# MCU_CTRL_MMR0_MCU_CTRL_MMR_CFG0_04500000h register map
Vendor: Texas Instruments
Peripheral module from a debugger description file (folder AM275x).
Registers are 32-bit, read-write, reset 0x0 unless marked. A register's access mark holds for its fields unless they carry their own. Offsets are as the file gives them; lines under a group give offsets from that group; [hi:lo] are bit positions; {n}, {i} and the like mark numbered series; 'fields as' and 'values as' point back to an identical list; <NAME> marks a mode.

## mcu_ctrl_mmr_CFG0 (part 1 of 2)
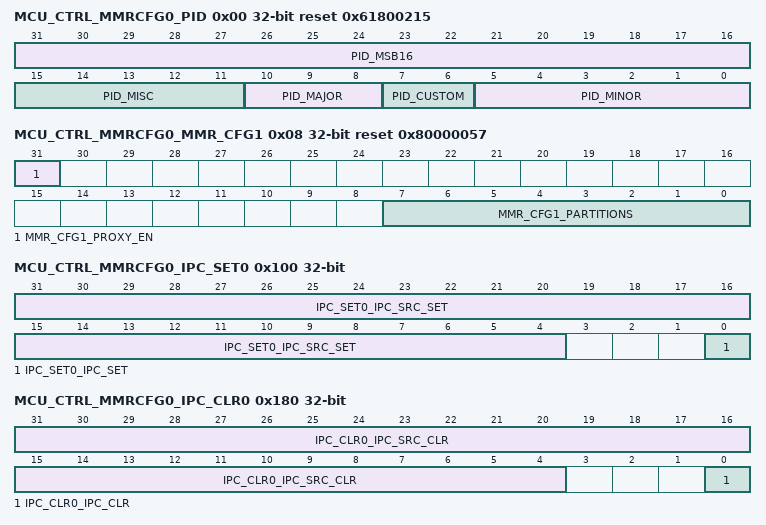
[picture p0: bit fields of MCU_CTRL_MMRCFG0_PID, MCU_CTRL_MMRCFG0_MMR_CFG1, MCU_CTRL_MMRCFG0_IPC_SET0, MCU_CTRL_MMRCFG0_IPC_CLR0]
0x00 MCU_CTRL_MMRCFG0_PID ro reset 0x61800215
  [31:16] PID_MSB16 — Reset Source: mod_g_rst_n
  [15:11] PID_MISC — Reset Source: mod_g_rst_n
  [10:8] PID_MAJOR — Reset Source: mod_g_rst_n
  [7:6] PID_CUSTOM — Reset Source: mod_g_rst_n
  [5:0] PID_MINOR — Reset Source: mod_g_rst_n
0x08 MCU_CTRL_MMRCFG0_MMR_CFG1 ro reset 0x80000057 — Indicates the MMR configuration
  [31] MMR_CFG1_PROXY_EN — Proxy addressing enabled Reset Source: mod_por_rst_n
  [7:0] MMR_CFG1_PARTITIONS — Indicates present partitions Reset Source: mod_por_rst_n
0x100 MCU_CTRL_MMRCFG0_IPC_SET0 access not given — Generate interprocessor communication interrupt to Device Manager
  [31:4] IPC_SET0_IPC_SRC_SET — Read returns 0Write: 0 - No effect 1 - Sets both corresponding IPC_CLR and the IPC_SET bits Reset Source: mod_g_rst_n (access R/W1TS)
  [0] IPC_SET0_IPC_SET — Read returns 0Write: 0 - No effect 1 - Sets both corresponding IPC_CLR and the IPC_SET bits Reset Source: mod_g_rst_n (access R/W1TS)
0x180 MCU_CTRL_MMRCFG0_IPC_CLR0 access not given — Acknowledge interprocessor communication interrupt to Device Manager
  [31:4] IPC_CLR0_IPC_SRC_CLR — Read returns current valueWrite: 0 - No effect 1 - Clears both corresponding IPC_CLR and the IPC_SET bits Reset Source: mod_g_rst_n (access R/W1TC)
  [0] IPC_CLR0_IPC_CLR — Read returns current valueWrite: 0 - No effect 1 - Clears both corresponding IPC_CLR and the IPC_SET bits Reset Source: mod_g_rst_n (access R/W1TC)
0x270 MCU_CTRL_MMRCFG0_CBA_ERR_STAT ro — Indicates addressing errors on the bus segments. Software can read this register upon receiving an mcu_cbass_err interrupt to determine the bus segment on which the error occurred.
  [24] CBA_ERR_STAT_WKUP_SAFE_CBA_ERR — Access Error from Wkup Safe CBASSField values (others are reserved):1'b0 - NO_ERROR1'b1 - ERROR Reset Source: mod_g_rst_n
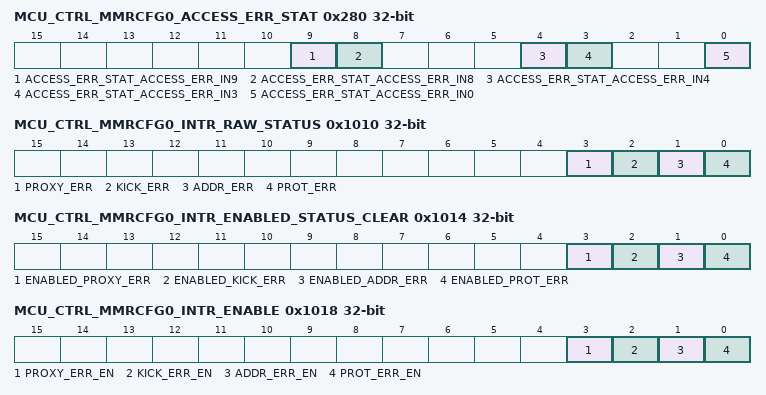
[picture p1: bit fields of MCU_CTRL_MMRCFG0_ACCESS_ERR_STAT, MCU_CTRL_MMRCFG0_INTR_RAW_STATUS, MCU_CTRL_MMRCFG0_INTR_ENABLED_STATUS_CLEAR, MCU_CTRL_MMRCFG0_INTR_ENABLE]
0x280 MCU_CTRL_MMRCFG0_ACCESS_ERR_STAT ro — Indicates an SoC MMR module access error. Software can read this register upon receiving an soc_access_err interrupt to determine the MMR module(s) where the error occurred. Interrupt status registers within the indicated MMR will provide additional details on the type of error. The access error must be cleared within the MMR for the associated access_err_in bit to be cleared.
  [9] ACCESS_ERR_STAT_ACCESS_ERR_IN9 — Access Error From MCU_PADCFG_CTRL0 MMRField values (others are reserved):1'b0 - NO_ERROR1'b1 - ERROR Reset Source: mod_por_rst_n
  [8] ACCESS_ERR_STAT_ACCESS_ERR_IN8 — Access Error From WKUP_CTRL_MMR1Field values (others are reserved):1'b0 - NO_ERROR1'b1 - ERROR Reset Source: mod_por_rst_n
  [4] ACCESS_ERR_STAT_ACCESS_ERR_IN4 — Access Error From PADCFG_CTRL0 MMRField values (others are reserved):1'b0 - NO_ERROR1'b1 - ERROR Reset Source: mod_por_rst_n
  [3] ACCESS_ERR_STAT_ACCESS_ERR_IN3 — Access Error From CTRL_MMR0Field values (others are reserved):1'b0 - NO_ERROR1'b1 - ERROR Reset Source: mod_por_rst_n
  [0] ACCESS_ERR_STAT_ACCESS_ERR_IN0 — Access Error From WKUP_CTRL_MMR0Field values (others are reserved):1'b0 - NO_ERROR1'b1 - ERROR Reset Source: mod_por_rst_n
{0x1008+0x4000*i} MCU_CTRL_MMRCFG0_LOCK{i}_KICK0 (i=0..2)
  [31:0] LOCK{i}_KICK0 — - KICK0 component Reset Source: mod_g_rst_n
{0x100C+0x4000*i} MCU_CTRL_MMRCFG0_LOCK{i}_KICK1 (i=0..2)
  [31:0] LOCK{i}_KICK1 — - KICK1 component Reset Source: mod_g_rst_n
0x1010 MCU_CTRL_MMRCFG0_INTR_RAW_STATUS access not given
  [3] PROXY_ERR — Proxy0 access violation error. Raw status is read. Write a 1 to set the status. Writing a 0 has no effect. Reset Source: mod_g_rst_n (access R/W1TS)
  [2] KICK_ERR — Kick access violation error. Raw status is read. Write a 1 to set the status. Writing a 0 has no effect. Reset Source: mod_g_rst_n (access R/W1TS)
  [1] ADDR_ERR — Addressing violation error. Raw status is read. Write a 1 to set the status. Writing a 0 has no effect. Reset Source: mod_g_rst_n (access R/W1TS)
  [0] PROT_ERR — Protection violation error. Raw status is read. Write a 1 to set the status. Writing a 0 has no effect. Reset Source: mod_g_rst_n (access R/W1TS)
0x1014 MCU_CTRL_MMRCFG0_INTR_ENABLED_STATUS_CLEAR access not given
  [3] ENABLED_PROXY_ERR — Proxy0 access violation error. Enabled status is read. Write a 1 to clear the status. Writing a 0 has no effect. Reset Source: mod_g_rst_n (access R/W1TC)
  [2] ENABLED_KICK_ERR — Kick access violation error. Enabled status is read. Write a 1 to clear the status. Writing a 0 has no effect. Reset Source: mod_g_rst_n (access R/W1TC)
  [1] ENABLED_ADDR_ERR — Addressing violation error. Enabled status is read. Write a 1 to clear the status. Writing a 0 has no effect. Reset Source: mod_g_rst_n (access R/W1TC)
  [0] ENABLED_PROT_ERR — Protection violation error. Enabled status is read. Write a 1 to clear the status. Writing a 0 has no effect. Reset Source: mod_g_rst_n (access R/W1TC)
0x1018 MCU_CTRL_MMRCFG0_INTR_ENABLE access not given
  [3] PROXY_ERR_EN — Proxy0 access violation error enable. Write a 1 to set the enable. Writing a 0 has no effect. Reset Source: mod_g_rst_n (access R/W1TS)
  [2] KICK_ERR_EN — Kick access violation error enable. Write a 1 to set the enable. Writing a 0 has no effect. Reset Source: mod_g_rst_n (access R/W1TS)
  [1] ADDR_ERR_EN — Addressing violation error enable. Write a 1 to set the enable. Writing a 0 has no effect. Reset Source: mod_g_rst_n (access R/W1TS)
  [0] PROT_ERR_EN — Protection violation error enable. Write a 1 to set the enable. Writing a 0 has no effect. Reset Source: mod_g_rst_n (access R/W1TS)
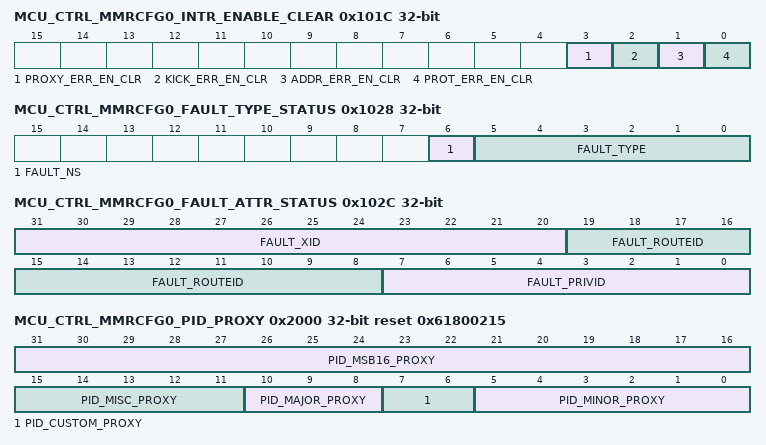
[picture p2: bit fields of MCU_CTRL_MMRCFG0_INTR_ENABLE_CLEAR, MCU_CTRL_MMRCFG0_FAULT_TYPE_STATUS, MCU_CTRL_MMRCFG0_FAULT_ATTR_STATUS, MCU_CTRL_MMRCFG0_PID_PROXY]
0x101C MCU_CTRL_MMRCFG0_INTR_ENABLE_CLEAR access not given
  [3] PROXY_ERR_EN_CLR — Proxy0 access violation error enable clear. Write a 1 to clear the enable. Writing a 0 has no effect. Reset Source: mod_g_rst_n (access R/W1TC)
  [2] KICK_ERR_EN_CLR — Kick access violation error enable clear. Write a 1 to clear the enable. Writing a 0 has no effect. Reset Source: mod_g_rst_n (access R/W1TC)
  [1] ADDR_ERR_EN_CLR — Addressing violation error enable clear. Write a 1 to clear the enable. Writing a 0 has no effect. Reset Source: mod_g_rst_n (access R/W1TC)
  [0] PROT_ERR_EN_CLR — Protection violation error enable clear. Write a 1 to clear the enable. Writing a 0 has no effect. Reset Source: mod_g_rst_n (access R/W1TC)
0x1020 MCU_CTRL_MMRCFG0_EOI
  [7:0] EOI_VECTOR — EOI vector value. Write this with interrupt distribution value in the chip. Reset Source: mod_g_rst_n
0x1024 MCU_CTRL_MMRCFG0_FAULT_ADDRESS ro
  [31:0] FAULT_ADDR — Fault Address. Reset Source: mod_g_rst_n
0x1028 MCU_CTRL_MMRCFG0_FAULT_TYPE_STATUS ro
  [6] FAULT_NS — Non-secure access. Reset Source: mod_g_rst_n
  [5:0] FAULT_TYPE — Fault Type 10_0000 = Supervisor read fault - priv = 1 dir = 1 dtype != 1 01_0000 = Supervisor write fault - priv = 1 dir = 0 00_1000 = Supervisor execute fault - priv = 1 dir = 1 dtype = 1 00_0100 = User read fault - priv = 0 dir = 1 dtype = 1 00_0010 = User write fault - priv = 0 dir = 0 00_0001 = User execute fault - priv = 0 dir = 1 dtype = 1 00_0000 = No fault Reset Source: mod_g_rst_n
0x102C MCU_CTRL_MMRCFG0_FAULT_ATTR_STATUS ro
  [31:20] FAULT_XID — XID. Reset Source: mod_g_rst_n
  [19:8] FAULT_ROUTEID — Route ID. Reset Source: mod_g_rst_n
  [7:0] FAULT_PRIVID — Privilege ID. Reset Source: mod_g_rst_n
0x1030 MCU_CTRL_MMRCFG0_FAULT_CLEAR wo
  [0] FAULT_CLR — Fault clear. Writing a 1 clears the current fault. Writing a 0 has no effect. Reset Source: mod_g_rst_n
0x1100 MCU_CTRL_MMRCFG0_CLAIMREG_P0_R0_READONLY ro
  [31:0] CLAIMREG_P0_R0_READONLY — Claim bits for Partition 0 Reset Source: mod_g_rst_n
{0x1100+4i} MCU_CTRL_MMRCFG0_CLAIMREG_P0_R{i}_READONLY ro (i=2..5)
  [31:0] CLAIMREG_P0_R{i}_READONLY — Claim bits for Partition 0 Reset Source: mod_g_rst_n
0x2000 MCU_CTRL_MMRCFG0_PID_PROXY ro reset 0x61800215
  [31:16] PID_MSB16_PROXY — Reset Source: mod_g_rst_n
  [15:11] PID_MISC_PROXY — Reset Source: mod_g_rst_n
  [10:8] PID_MAJOR_PROXY — Reset Source: mod_g_rst_n
  [7:6] PID_CUSTOM_PROXY — Reset Source: mod_g_rst_n
  [5:0] PID_MINOR_PROXY — Reset Source: mod_g_rst_n
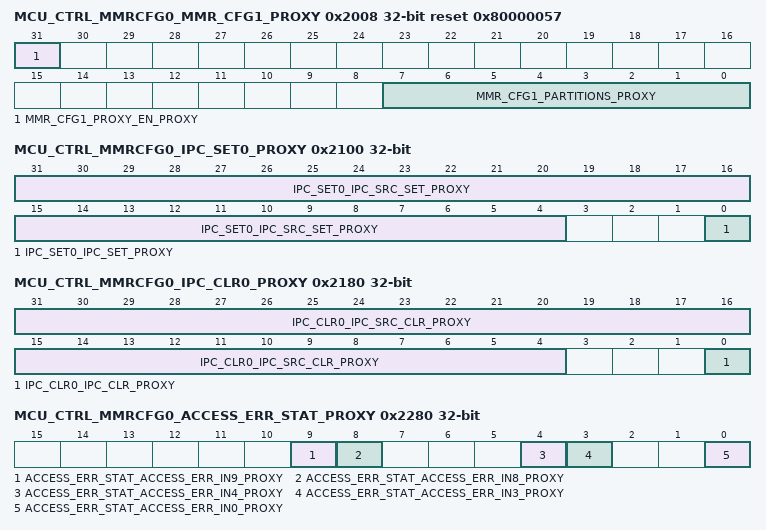
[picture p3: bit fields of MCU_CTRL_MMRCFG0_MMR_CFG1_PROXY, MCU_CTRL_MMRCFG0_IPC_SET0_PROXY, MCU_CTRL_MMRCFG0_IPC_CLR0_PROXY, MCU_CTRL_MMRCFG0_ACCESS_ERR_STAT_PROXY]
0x2008 MCU_CTRL_MMRCFG0_MMR_CFG1_PROXY ro reset 0x80000057 — Indicates the MMR configuration
  [31] MMR_CFG1_PROXY_EN_PROXY — Proxy addressing enabled Reset Source: mod_por_rst_n
  [7:0] MMR_CFG1_PARTITIONS_PROXY — Indicates present partitions Reset Source: mod_por_rst_n
0x2100 MCU_CTRL_MMRCFG0_IPC_SET0_PROXY access not given — Generate interprocessor communication interrupt to Device Manager
  [31:4] IPC_SET0_IPC_SRC_SET_PROXY — Read returns 0Write: 0 - No effect 1 - Sets both corresponding IPC_CLR and the IPC_SET bits Reset Source: mod_g_rst_n (access R/W1TS)
  [0] IPC_SET0_IPC_SET_PROXY — Read returns 0Write: 0 - No effect 1 - Sets both corresponding IPC_CLR and the IPC_SET bits Reset Source: mod_g_rst_n (access R/W1TS)
0x2180 MCU_CTRL_MMRCFG0_IPC_CLR0_PROXY access not given — Acknowledge interprocessor communication interrupt to Device Manager
  [31:4] IPC_CLR0_IPC_SRC_CLR_PROXY — Read returns current valueWrite: 0 - No effect 1 - Clears both corresponding IPC_CLR and the IPC_SET bits Reset Source: mod_g_rst_n (access R/W1TC)
  [0] IPC_CLR0_IPC_CLR_PROXY — Read returns current valueWrite: 0 - No effect 1 - Clears both corresponding IPC_CLR and the IPC_SET bits Reset Source: mod_g_rst_n (access R/W1TC)
0x2270 MCU_CTRL_MMRCFG0_CBA_ERR_STAT_PROXY ro — Indicates addressing errors on the bus segments. Software can read this register upon receiving an mcu_cbass_err interrupt to determine the bus segment on which the error occurred.
  [24] CBA_ERR_STAT_WKUP_SAFE_CBA_ERR_PROXY — Access Error from Wkup Safe CBASSField values (others are reserved):1'b0 - NO_ERROR1'b1 - ERROR Reset Source: mod_g_rst_n
0x2280 MCU_CTRL_MMRCFG0_ACCESS_ERR_STAT_PROXY ro — Indicates an SoC MMR module access error. Software can read this register upon receiving an soc_access_err interrupt to determine the MMR module(s) where the error occurred. Interrupt status registers within the indicated MMR will provide additional details on the type of error. The access error must be cleared within the MMR for the associated access_err_in bit to be cleared.
  [9] ACCESS_ERR_STAT_ACCESS_ERR_IN9_PROXY — Access Error From MCU_PADCFG_CTRL0 MMRField values (others are reserved):1'b0 - NO_ERROR1'b1 - ERROR Reset Source: mod_por_rst_n
  [8] ACCESS_ERR_STAT_ACCESS_ERR_IN8_PROXY — Access Error From WKUP_CTRL_MMR1Field values (others are reserved):1'b0 - NO_ERROR1'b1 - ERROR Reset Source: mod_por_rst_n
  [4] ACCESS_ERR_STAT_ACCESS_ERR_IN4_PROXY — Access Error From PADCFG_CTRL0 MMRField values (others are reserved):1'b0 - NO_ERROR1'b1 - ERROR Reset Source: mod_por_rst_n
  [3] ACCESS_ERR_STAT_ACCESS_ERR_IN3_PROXY — Access Error From CTRL_MMR0Field values (others are reserved):1'b0 - NO_ERROR1'b1 - ERROR Reset Source: mod_por_rst_n
  [0] ACCESS_ERR_STAT_ACCESS_ERR_IN0_PROXY — Access Error From WKUP_CTRL_MMR0Field values (others are reserved):1'b0 - NO_ERROR1'b1 - ERROR Reset Source: mod_por_rst_n
{0x3008+0x4000*i} MCU_CTRL_MMRCFG0_LOCK{i}_KICK0_PROXY (i=0..2)
  [31:0] LOCK{i}_KICK0_PROXY — - KICK0 component Reset Source: mod_g_rst_n
{0x300C+0x4000*i} MCU_CTRL_MMRCFG0_LOCK{i}_KICK1_PROXY (i=0..2)
  [31:0] LOCK{i}_KICK1_PROXY — - KICK1 component Reset Source: mod_g_rst_n
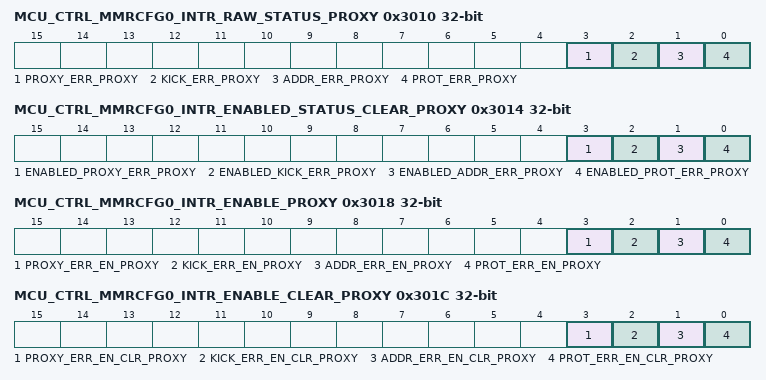
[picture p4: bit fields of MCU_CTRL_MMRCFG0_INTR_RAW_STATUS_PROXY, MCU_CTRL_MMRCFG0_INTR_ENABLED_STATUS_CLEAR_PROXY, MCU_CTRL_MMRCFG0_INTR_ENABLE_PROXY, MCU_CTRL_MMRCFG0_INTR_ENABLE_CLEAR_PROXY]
0x3010 MCU_CTRL_MMRCFG0_INTR_RAW_STATUS_PROXY access not given
  [3] PROXY_ERR_PROXY — Proxy0 access violation error. Raw status is read. Write a 1 to set the status. Writing a 0 has no effect. Reset Source: mod_g_rst_n (access R/W1TS)
  [2] KICK_ERR_PROXY — Kick access violation error. Raw status is read. Write a 1 to set the status. Writing a 0 has no effect. Reset Source: mod_g_rst_n (access R/W1TS)
  [1] ADDR_ERR_PROXY — Addressing violation error. Raw status is read. Write a 1 to set the status. Writing a 0 has no effect. Reset Source: mod_g_rst_n (access R/W1TS)
  [0] PROT_ERR_PROXY — Protection violation error. Raw status is read. Write a 1 to set the status. Writing a 0 has no effect. Reset Source: mod_g_rst_n (access R/W1TS)
0x3014 MCU_CTRL_MMRCFG0_INTR_ENABLED_STATUS_CLEAR_PROXY access not given
  [3] ENABLED_PROXY_ERR_PROXY — Proxy0 access violation error. Enabled status is read. Write a 1 to clear the status. Writing a 0 has no effect. Reset Source: mod_g_rst_n (access R/W1TC)
  [2] ENABLED_KICK_ERR_PROXY — Kick access violation error. Enabled status is read. Write a 1 to clear the status. Writing a 0 has no effect. Reset Source: mod_g_rst_n (access R/W1TC)
  [1] ENABLED_ADDR_ERR_PROXY — Addressing violation error. Enabled status is read. Write a 1 to clear the status. Writing a 0 has no effect. Reset Source: mod_g_rst_n (access R/W1TC)
  [0] ENABLED_PROT_ERR_PROXY — Protection violation error. Enabled status is read. Write a 1 to clear the status. Writing a 0 has no effect. Reset Source: mod_g_rst_n (access R/W1TC)
0x3018 MCU_CTRL_MMRCFG0_INTR_ENABLE_PROXY access not given
  [3] PROXY_ERR_EN_PROXY — Proxy0 access violation error enable. Write a 1 to set the enable. Writing a 0 has no effect. Reset Source: mod_g_rst_n (access R/W1TS)
  [2] KICK_ERR_EN_PROXY — Kick access violation error enable. Write a 1 to set the enable. Writing a 0 has no effect. Reset Source: mod_g_rst_n (access R/W1TS)
  [1] ADDR_ERR_EN_PROXY — Addressing violation error enable. Write a 1 to set the enable. Writing a 0 has no effect. Reset Source: mod_g_rst_n (access R/W1TS)
  [0] PROT_ERR_EN_PROXY — Protection violation error enable. Write a 1 to set the enable. Writing a 0 has no effect. Reset Source: mod_g_rst_n (access R/W1TS)
0x301C MCU_CTRL_MMRCFG0_INTR_ENABLE_CLEAR_PROXY access not given
  [3] PROXY_ERR_EN_CLR_PROXY — Proxy0 access violation error enable clear. Write a 1 to clear the enable. Writing a 0 has no effect. Reset Source: mod_g_rst_n (access R/W1TC)
  [2] KICK_ERR_EN_CLR_PROXY — Kick access violation error enable clear. Write a 1 to clear the enable. Writing a 0 has no effect. Reset Source: mod_g_rst_n (access R/W1TC)
  [1] ADDR_ERR_EN_CLR_PROXY — Addressing violation error enable clear. Write a 1 to clear the enable. Writing a 0 has no effect. Reset Source: mod_g_rst_n (access R/W1TC)
  [0] PROT_ERR_EN_CLR_PROXY — Protection violation error enable clear. Write a 1 to clear the enable. Writing a 0 has no effect. Reset Source: mod_g_rst_n (access R/W1TC)
0x3020 MCU_CTRL_MMRCFG0_EOI_PROXY
  [7:0] EOI_VECTOR_PROXY — EOI vector value. Write this with interrupt distribution value in the chip. Reset Source: mod_g_rst_n
0x3024 MCU_CTRL_MMRCFG0_FAULT_ADDRESS_PROXY ro
  [31:0] FAULT_ADDR_PROXY — Fault Address. Reset Source: mod_g_rst_n
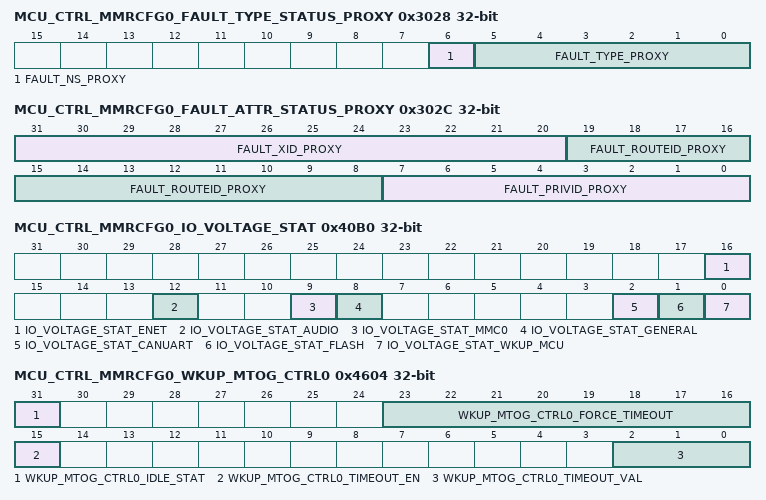
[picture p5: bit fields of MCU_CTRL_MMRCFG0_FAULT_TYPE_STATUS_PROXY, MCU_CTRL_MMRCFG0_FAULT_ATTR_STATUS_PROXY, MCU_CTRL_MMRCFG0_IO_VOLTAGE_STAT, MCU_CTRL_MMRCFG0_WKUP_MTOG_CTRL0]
0x3028 MCU_CTRL_MMRCFG0_FAULT_TYPE_STATUS_PROXY ro
  [6] FAULT_NS_PROXY — Non-secure access. Reset Source: mod_g_rst_n
  [5:0] FAULT_TYPE_PROXY — Fault Type 10_0000 = Supervisor read fault - priv = 1 dir = 1 dtype != 1 01_0000 = Supervisor write fault - priv = 1 dir = 0 00_1000 = Supervisor execute fault - priv = 1 dir = 1 dtype = 1 00_0100 = User read fault - priv = 0 dir = 1 dtype = 1 00_0010 = User write fault - priv = 0 dir = 0 00_0001 = User execute fault - priv = 0 dir = 1 dtype = 1 00_0000 = No fault Reset Source: mod_g_rst_n
0x302C MCU_CTRL_MMRCFG0_FAULT_ATTR_STATUS_PROXY ro
  [31:20] FAULT_XID_PROXY — XID. Reset Source: mod_g_rst_n
  [19:8] FAULT_ROUTEID_PROXY — Route ID. Reset Source: mod_g_rst_n
  [7:0] FAULT_PRIVID_PROXY — Privilege ID. Reset Source: mod_g_rst_n
0x3030 MCU_CTRL_MMRCFG0_FAULT_CLEAR_PROXY wo
  [0] FAULT_CLR_PROXY — Fault clear. Writing a 1 clears the current fault. Writing a 0 has no effect. Reset Source: mod_g_rst_n
{0x3100+4i} MCU_CTRL_MMRCFG0_CLAIMREG_P0_R{i} (i=0..5)
  [31:0] CLAIMREG_P0_R{i} — Claim bits for Partition 0 Reset Source: mod_g_rst_n
0x4020 MCU_CTRL_MMRCFG0_MCU_GPIO_CTRL — Controls operation of the MCU_GPIO module
  [0] MCU_GPIO_CTRL_WAKEN — Determines whether or not MCU_GPIO clock is stopped by its LPSC. Preventing the clock stop allows the MCU_GPIO to provide a wakeup event.Field values (others are reserved):1'b0 - WAKEUP_DISABLED1'b1 - WAKEUP_ENABLED Reset Source: mod_por_rst_n
{0x4080+4i} MCU_CTRL_MMRCFG0_DBOUNCE_CFG{i} (i=1..6) — Configures IO debounce selections
  [5:0] DBOUNCE_CFG{i}_DB_CFG — Configures the debounce period used for I/Os with PADCONFIGx_DEBOUNCE_SEL = {i}. Debounce period is specified as a number of CLK0 or CLK1 clock cycles. For all inputs CLK0 is CLK_32K_RC and CLK1 is HFOSC0_CLKOUT.Field values (others are reserved):6'b000000 - BYPASS6'b000001 - DB_64_CLK06'b000010 - DB_96_CLK06'b000011 - DB_128_CLK06'b000100 - DB_160_CLK06'b000101 - DB_192_CLK06'b000110 - DB_224_CLK06'b000111 - DB_256_CLK06'b001000 - DB_288_CLK06'b001001 - DB_320_CLK06'b001010 - DB_352_CLK06'b001011 - DB_384_CLK06'b001100 - DB_416_CLK06'b001101 - DB_448_CLK06'b001110 - DB_480_CLK06'b001111 - DB_512_CLK06'b010000 - DB_544_CLK06'b010001 - DB_576_CLK06'b010010 - DB_608_CLK06'b010011 - DB_640_CLK06'b010100 - DB_672_CLK06'b010101 - DB_704_CLK06'b010110 - DB_512_CLK06'b010111 - DB_1024_CLK06'b011000 - DB_1536_CLK06'b011001 - DB_2048_CLK06'b011010 - DB_2560_CLK06'b011011 - DB_3072_CLK06'b011100 - DB_3584_CLK06'b011101 - DB_4096_CLK06'b011110 - DB_4608_CLK06'b011111 - DB_5120_CLK06'b100000 - DB_1_CLK16'b100001 - DB_2_CLK16'b100010 - DB_3_CLK16'b100011 - DB_4_CLK16'b100100 - DB_5_CLK16'b100101 - DB_6_CLK16'b100110 - DB_7_CLK16'b100111 - DB_8_CLK16'b101000 - DB_9_CLK16'b101001 - DB_10_CLK16'b101010 - DB_11_CLK16'b101011 - DB_12_CLK16'b101100 - DB_13_CLK16'b101101 - DB_14_CLK16'b101110 - DB_15_CLK16'b101111 - DB_16_CLK16'b110000 - DB_17_CLK16'b110001 - DB_18_CLK16'b110010 - DB_19_CLK16'b110011 - DB_20_CLK16'b110100 - DB_21_CLK16'b110101 - DB_22_CLK16'b110110 - DB_512_CLK16'b110111 - DB_1024_CLK16'b111000 - DB_1536_CLK16'b111001 - DB_2048_CLK16'b111010 - DB_2560_CLK16'b111011 - DB_3072_CLK16'b111100 - DB_3584_CLK16'b111101 - DB_4096_CLK16'b111110 - DB_4608_CLK16'b111111 - DB_5120_CLK1 Reset Source: mod_por_rst_n
0x40B0 MCU_CTRL_MMRCFG0_IO_VOLTAGE_STAT ro — Reads returns the current value detected by the IO voltage mode circuit for each dual rail I/O Group.
  [16] IO_VOLTAGE_STAT_ENET — Detected voltage for the ENET I/O group (VDDSHV2)Field values (others are reserved):1'b0 - IOGROUP_3P3V1'b1 - IOGROUP_1P8V Reset Source: mod_por_rst_n
  [12] IO_VOLTAGE_STAT_AUDIO — Detected voltage for the AUDIO I/O group (VDDSHV3)Field values (others are reserved):1'b0 - IOGROUP_3P3V1'b1 - IOGROUP_1P8V Reset Source: mod_por_rst_n
  [9] IO_VOLTAGE_STAT_MMC0 — Detected voltage for the MMC0 I/O group (VDDSHV4)Field values (others are reserved):1'b0 - IOGROUP_3P3V1'b1 - IOGROUP_1P8V Reset Source: mod_por_rst_n
  [8] IO_VOLTAGE_STAT_GENERAL — Detected voltage for the General I/O group (VDDSHV0)Field values (others are reserved):1'b0 - IOGROUP_3P3V1'b1 - IOGROUP_1P8V Reset Source: mod_por_rst_n
  [2] IO_VOLTAGE_STAT_CANUART — Detected voltage for the CANUART I/O group (VDDSHV_WKUP)Field values (others are reserved):1'b0 - IOGROUP_3P3V1'b1 - IOGROUP_1P8V Reset Source: mod_por_rst_n
  [1] IO_VOLTAGE_STAT_FLASH — Detected voltage for the Flash I/O group (VDDSHV1)Field values (others are reserved):1'b0 - IOGROUP_3P3V1'b1 - IOGROUP_1P8V Reset Source: mod_por_rst_n
  [0] IO_VOLTAGE_STAT_WKUP_MCU — Detected voltage for the WKUP_MCU I/O group (VDDSHV_MCU)Field values (others are reserved):1'b0 - IOGROUP_3P3V1'b1 - IOGROUP_1P8V Reset Source: mod_por_rst_n
0x4604 MCU_CTRL_MMRCFG0_WKUP_MTOG_CTRL0 access per field — Controls the dm2ws WKUP_TIMEOUT0 gasket
  [31] WKUP_MTOG_CTRL0_IDLE_STAT ro — Idle statusWhen high, indicates MTOGundefined is idle.Field values (others are reserved):1'b0 - BUSY1'b1 - IDLE Reset Source: mod_g_rst_n
  [23:16] WKUP_MTOG_CTRL0_FORCE_TIMEOUT rw — Force TimoutThis is a fault tolerant bitfield.Forces a flush of the interface transactions. This bitfield is only relevant if timeout_en=1. After forcing a timeout by Writing the encoded value, the force_timeout and timeout_en bitfields mut be cleared to clear the timeout before re-enabling the gasket.Field values (others are reserved):8'h00 - CLEAR_TIMEOUT8'h95 - FORCE_TIMEOUT Reset Source: mod_g_rst_n
  [15] WKUP_MTOG_CTRL0_TIMEOUT_EN rw — Timeout Gasket EnableField values (others are reserved):1'b0 - DISABLED (write 0 to clear the interrupt and reset the gasket counter)1'b1 - ENABLED Reset Source: mod_g_rst_n
  [2:0] WKUP_MTOG_CTRL0_TIMEOUT_VAL rw — Gasket Timeout ValueSelects the number of clock cycles before the interface is considered to have timed outField values (others are reserved):3'b000 - TO_1K_CYCLES3'b001 - TO_4K_CYCLES3'b010 - TO_16K_CYCLES3'b011 - TO_64K_CYCLES3'b100 - TO_256K_CYCLES3'b101 - TO_1024K_CYCLES3'b110 - TO_2048K_CYCLES3'b111 - TO_4096K_CYCLES Reset Source: mod_g_rst_n
0x4610 MCU_CTRL_MMRCFG0_TOG_STAT ro — Contains the status of each Timeout Gasket, to be read in ISR to determine which timeout gasket caused an interrupt.
  [1:0] TOG_STAT_MST_TOG_STAT — Error Status of Initiator Timeout GasketsField values (others are reserved):undefined - undefinedundefined - undefined2'b01 - RESERVED2'b10 - WKUP_TIMEOUT0undefined - undefined2'b11 - RESERVED Reset Source: mod_g_rst_n
{0x5100+4i} MCU_CTRL_MMRCFG0_CLAIMREG_P1_R{i}_READONLY ro (i=0..2)
  [31:0] CLAIMREG_P1_R{i}_READONLY — Claim bits for Partition 1 Reset Source: mod_g_rst_n
0x6020 MCU_CTRL_MMRCFG0_MCU_GPIO_CTRL_PROXY — Controls operation of the MCU_GPIO module
  [0] MCU_GPIO_CTRL_WAKEN_PROXY — Determines whether or not MCU_GPIO clock is stopped by its LPSC. Preventing the clock stop allows the MCU_GPIO to provide a wakeup event.Field values (others are reserved):1'b0 - WAKEUP_DISABLED1'b1 - WAKEUP_ENABLED Reset Source: mod_por_rst_n
{0x6080+4i} MCU_CTRL_MMRCFG0_DBOUNCE_CFG{i}_PROXY (i=1..6) — Configures IO debounce selections
  [5:0] DBOUNCE_CFG{i}_DB_CFG_PROXY — Configures the debounce period used for I/Os with PADCONFIGx_DEBOUNCE_SEL = {i}. Debounce period is specified as a number of CLK0 or CLK1 clock cycles. For all inputs CLK0 is CLK_32K_RC and CLK1 is HFOSC0_CLKOUT.Field values (others are reserved):6'b000000 - BYPASS6'b000001 - DB_64_CLK06'b000010 - DB_96_CLK06'b000011 - DB_128_CLK06'b000100 - DB_160_CLK06'b000101 - DB_192_CLK06'b000110 - DB_224_CLK06'b000111 - DB_256_CLK06'b001000 - DB_288_CLK06'b001001 - DB_320_CLK06'b001010 - DB_352_CLK06'b001011 - DB_384_CLK06'b001100 - DB_416_CLK06'b001101 - DB_448_CLK06'b001110 - DB_480_CLK06'b001111 - DB_512_CLK06'b010000 - DB_544_CLK06'b010001 - DB_576_CLK06'b010010 - DB_608_CLK06'b010011 - DB_640_CLK06'b010100 - DB_672_CLK06'b010101 - DB_704_CLK06'b010110 - DB_512_CLK06'b010111 - DB_1024_CLK06'b011000 - DB_1536_CLK06'b011001 - DB_2048_CLK06'b011010 - DB_2560_CLK06'b011011 - DB_3072_CLK06'b011100 - DB_3584_CLK06'b011101 - DB_4096_CLK06'b011110 - DB_4608_CLK06'b011111 - DB_5120_CLK06'b100000 - DB_1_CLK16'b100001 - DB_2_CLK16'b100010 - DB_3_CLK16'b100011 - DB_4_CLK16'b100100 - DB_5_CLK16'b100101 - DB_6_CLK16'b100110 - DB_7_CLK16'b100111 - DB_8_CLK16'b101000 - DB_9_CLK16'b101001 - DB_10_CLK16'b101010 - DB_11_CLK16'b101011 - DB_12_CLK16'b101100 - DB_13_CLK16'b101101 - DB_14_CLK16'b101110 - DB_15_CLK16'b101111 - DB_16_CLK16'b110000 - DB_17_CLK16'b110001 - DB_18_CLK16'b110010 - DB_19_CLK16'b110011 - DB_20_CLK16'b110100 - DB_21_CLK16'b110101 - DB_22_CLK16'b110110 - DB_512_CLK16'b110111 - DB_1024_CLK16'b111000 - DB_1536_CLK16'b111001 - DB_2048_CLK16'b111010 - DB_2560_CLK16'b111011 - DB_3072_CLK16'b111100 - DB_3584_CLK16'b111101 - DB_4096_CLK16'b111110 - DB_4608_CLK16'b111111 - DB_5120_CLK1 Reset Source: mod_por_rst_n
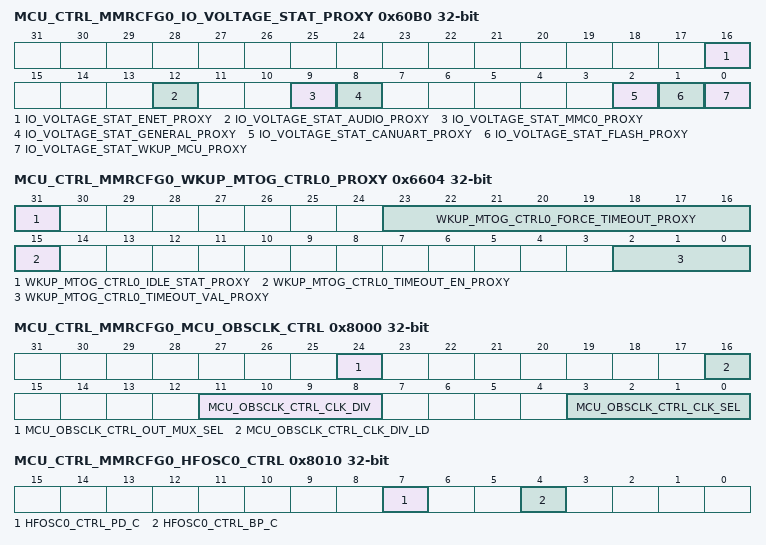
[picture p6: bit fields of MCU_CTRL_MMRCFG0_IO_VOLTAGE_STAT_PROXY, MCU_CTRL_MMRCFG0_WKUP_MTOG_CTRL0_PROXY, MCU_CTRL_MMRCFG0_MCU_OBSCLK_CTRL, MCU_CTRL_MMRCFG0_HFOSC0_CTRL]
0x60B0 MCU_CTRL_MMRCFG0_IO_VOLTAGE_STAT_PROXY ro — Reads returns the current value detected by the IO voltage mode circuit for each dual rail I/O Group.
  [16] IO_VOLTAGE_STAT_ENET_PROXY — Detected voltage for the ENET I/O group (VDDSHV2)Field values (others are reserved):1'b0 - IOGROUP_3P3V1'b1 - IOGROUP_1P8V Reset Source: mod_por_rst_n
  [12] IO_VOLTAGE_STAT_AUDIO_PROXY — Detected voltage for the AUDIO I/O group (VDDSHV3)Field values (others are reserved):1'b0 - IOGROUP_3P3V1'b1 - IOGROUP_1P8V Reset Source: mod_por_rst_n
  [9] IO_VOLTAGE_STAT_MMC0_PROXY — Detected voltage for the MMC0 I/O group (VDDSHV4)Field values (others are reserved):1'b0 - IOGROUP_3P3V1'b1 - IOGROUP_1P8V Reset Source: mod_por_rst_n
  [8] IO_VOLTAGE_STAT_GENERAL_PROXY — Detected voltage for the General I/O group (VDDSHV0)Field values (others are reserved):1'b0 - IOGROUP_3P3V1'b1 - IOGROUP_1P8V Reset Source: mod_por_rst_n
  [2] IO_VOLTAGE_STAT_CANUART_PROXY — Detected voltage for the CANUART I/O group (VDDSHV_WKUP)Field values (others are reserved):1'b0 - IOGROUP_3P3V1'b1 - IOGROUP_1P8V Reset Source: mod_por_rst_n
  [1] IO_VOLTAGE_STAT_FLASH_PROXY — Detected voltage for the Flash I/O group (VDDSHV1)Field values (others are reserved):1'b0 - IOGROUP_3P3V1'b1 - IOGROUP_1P8V Reset Source: mod_por_rst_n
  [0] IO_VOLTAGE_STAT_WKUP_MCU_PROXY — Detected voltage for the WKUP_MCU I/O group (VDDSHV_MCU)Field values (others are reserved):1'b0 - IOGROUP_3P3V1'b1 - IOGROUP_1P8V Reset Source: mod_por_rst_n
0x6604 MCU_CTRL_MMRCFG0_WKUP_MTOG_CTRL0_PROXY access per field — Controls the dm2ws WKUP_TIMEOUT0 gasket
  [31] WKUP_MTOG_CTRL0_IDLE_STAT_PROXY ro — Idle statusWhen high, indicates MTOGundefined is idle.Field values (others are reserved):1'b0 - BUSY1'b1 - IDLE Reset Source: mod_g_rst_n
  [23:16] WKUP_MTOG_CTRL0_FORCE_TIMEOUT_PROXY rw — Force TimoutThis is a fault tolerant bitfield.Forces a flush of the interface transactions. This bitfield is only relevant if timeout_en=1. After forcing a timeout by Writing the encoded value, the force_timeout and timeout_en bitfields mut be cleared to clear the timeout before re-enabling the gasket.Field values (others are reserved):8'h00 - CLEAR_TIMEOUT8'h95 - FORCE_TIMEOUT Reset Source: mod_g_rst_n
  [15] WKUP_MTOG_CTRL0_TIMEOUT_EN_PROXY rw — Timeout Gasket EnableField values (others are reserved):1'b0 - DISABLED (write 0 to clear the interrupt and reset the gasket counter)1'b1 - ENABLED Reset Source: mod_g_rst_n
  [2:0] WKUP_MTOG_CTRL0_TIMEOUT_VAL_PROXY rw — Gasket Timeout ValueSelects the number of clock cycles before the interface is considered to have timed outField values (others are reserved):3'b000 - TO_1K_CYCLES3'b001 - TO_4K_CYCLES3'b010 - TO_16K_CYCLES3'b011 - TO_64K_CYCLES3'b100 - TO_256K_CYCLES3'b101 - TO_1024K_CYCLES3'b110 - TO_2048K_CYCLES3'b111 - TO_4096K_CYCLES Reset Source: mod_g_rst_n
0x6610 MCU_CTRL_MMRCFG0_TOG_STAT_PROXY ro — Contains the status of each Timeout Gasket, to be read in ISR to determine which timeout gasket caused an interrupt.
  [1:0] TOG_STAT_MST_TOG_STAT_PROXY — Error Status of Initiator Timeout GasketsField values (others are reserved):undefined - undefinedundefined - undefined2'b01 - RESERVED2'b10 - WKUP_TIMEOUT0undefined - undefined2'b11 - RESERVED Reset Source: mod_g_rst_n
{0x7100+4i} MCU_CTRL_MMRCFG0_CLAIMREG_P1_R{i} (i=0..12)
  [31:0] CLAIMREG_P1_R{i} — Claim bits for Partition 1 Reset Source: mod_g_rst_n
0x8000 MCU_CTRL_MMRCFG0_MCU_OBSCLK_CTRL — Controls which internal clock is made observable on the MCU_OBSCLK output pin
  [24] MCU_OBSCLK_CTRL_OUT_MUX_SEL — MCU_OBSCLK pin output mux selection.Note, HFOSC0_CLK is a direct output from the HFOSC0, distinct from HFOSC0_CLKOUT.Note, when HFOSC0_CLK is selected (1'b1) the MCU_OBSCLK_CTRL_clk_sel field must be programmed to 4'b0001.Field values (others are reserved):1'b0 - CLK_DIV_OUT1'b1 - HFOSC0_CLK (clk_sel must be OFF) Reset Source: mod_por_rst_n
  [16] MCU_OBSCLK_CTRL_CLK_DIV_LD — Load the output divider valueWriting 1 to this bit will generate a load pulse to load the OBSCLK divider value. This bit can be cleared but must not be set in the same write cycle in which the clk_div value is changed. Field values (others are reserved):1'b0 - READY1'b1 - LOAD Reset Source: mod_por_rst_n
  [11:8] MCU_OBSCLK_CTRL_CLK_DIV — MCU_OBSCLK pin clock selection output dividerOutput clock is divided by clk_div+1 Reset Source: mod_por_rst_n
  [3:0] MCU_OBSCLK_CTRL_CLK_SEL — MCU_OBSCLK pin clock selectionField values (others are reserved):4'b0000 - CLK_12M_RC4'b0001 - OFF4'b0010 - MCU_PLL0_HSDIV0_CLKOUT4'b0011 - MCU_PLL0_HSDIV4_CLKOUT4'b0100 - MCU_PLLCTRL_OBSCLK4'b0101 - CLK_32K_RC4'b0110 - HFOSC0_CLKOUT4'b0111 - HFOSC0_CLKOUT_32K4'b1000 - MCU_SYSCLK04'b1001 - DEVICE_CLKOUT_32K Reset Source: mod_por_rst_n
0x8010 MCU_CTRL_MMRCFG0_HFOSC0_CTRL — Controls the operation of oscillator 0
  [7] HFOSC0_CTRL_PD_C — Oscillator powerdown control. When set, oscillator is disabled. Oscillator output is tristated if bp_c=0Field values (others are reserved):1'b0 - ACTIVE1'b1 - POWERDOWN Reset Source: mod_por_rst_n
  [4] HFOSC0_CTRL_BP_C — Must write '0' Reset Source: mod_por_rst_n
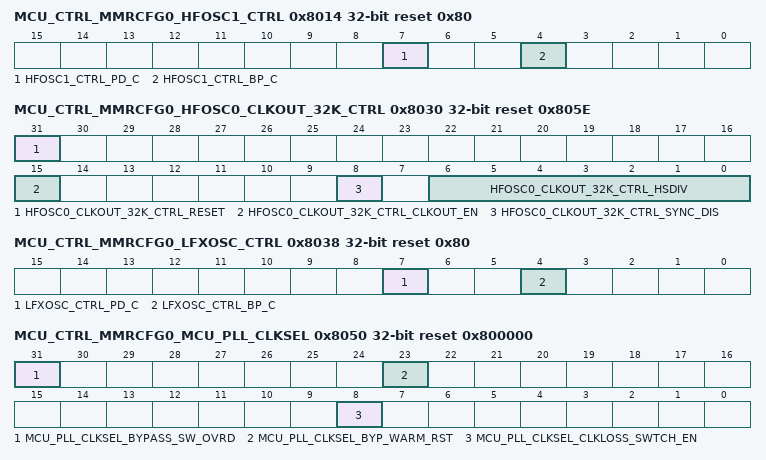
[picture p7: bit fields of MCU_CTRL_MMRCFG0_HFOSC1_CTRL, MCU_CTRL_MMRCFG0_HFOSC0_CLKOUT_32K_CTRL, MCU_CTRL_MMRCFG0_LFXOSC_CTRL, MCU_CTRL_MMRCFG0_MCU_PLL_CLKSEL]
0x8014 MCU_CTRL_MMRCFG0_HFOSC1_CTRL reset 0x80 — Controls the operation of oscillator 1
  [7] HFOSC1_CTRL_PD_C — Oscillator powerdown control. When set, oscillator is disabled. Oscillator output is tristated if bp_c=0Field values (others are reserved):1'b0 - ACTIVE1'b1 - POWERDOWN Reset Source: mod_por_rst_n
  [4] HFOSC1_CTRL_BP_C — Must write '0' Reset Source: mod_por_rst_n
0x8020 MCU_CTRL_MMRCFG0_HFOSC0_STAT access not given reset not defined — Allows status of the HFOSC Power Down by DM to be read by Top Level.
0x8030 MCU_CTRL_MMRCFG0_HFOSC0_CLKOUT_32K_CTRL reset 0x805E — Controls the HSDIV that generates a 32KHz RT clock from the HFOSC0 Crystal
  [31] HFOSC0_CLKOUT_32K_CTRL_RESET — Asynchronous Divider Reset.Field values (others are reserved):1'b0 - ACTIVE1'b1 - RESET Reset Source: sys_por_rst_n
  [15] HFOSC0_CLKOUT_32K_CTRL_CLKOUT_EN — HFOSC0_CLKOUT_32K output activeField values (others are reserved):1'b0 - Disabled1'b1 - Enabled Reset Source: sys_por_rst_n
  [8] HFOSC0_CLKOUT_32K_CTRL_SYNC_DIS — HFOSC0_CLKOUT_32K Synchronize DisableThis bit must be written 0.Field values (others are reserved):1'b0 - NORMAL Reset Source: sys_por_rst_n
  [6:0] HFOSC0_CLKOUT_32K_CTRL_HSDIV — HFOSC0_CLKOUT_32K divider:HFOSC0_CLKKOUT_32K Frequency = HFOSC0 Frequency / [8 * (hsdiv + 1)]Ex. HFOSC0 Frequency = 25MHz. hsdiv = 94 (Default)HFOSC0_CLKOUT_32K = 25MHz / (8 * (94+1)) = 26MHz / 760 = 32.894 kHz Reset Source: sys_por_rst_n
0x8038 MCU_CTRL_MMRCFG0_LFXOSC_CTRL reset 0x80 — Controls the operation of the low frequency oscillator
  [7] LFXOSC_CTRL_PD_C — Oscillator powerdown control. When set, oscillator is disabled. Oscillator output is tristated if bp_c=0Field values (others are reserved):1'b0 - ACTIVE1'b1 - POWERDOWN Reset Source: mod_por_rst_n
  [4] LFXOSC_CTRL_BP_C — Oscillator bypass control. When set, oscillator is in bypass modeField values (others are reserved):1'b0 - ACTIVE1'b1 - BYPASS Reset Source: mod_por_rst_n
0x8050 MCU_CTRL_MMRCFG0_MCU_PLL_CLKSEL reset 0x800000 — Controls the clock source for MCU PLL
  [31] MCU_PLL_CLKSEL_BYPASS_SW_OVRD — PLL Bypass warm reset software overrideWhen set, enables software control of exit from bypass mode on a mcu_reset_z for MCU_PLL0. This bit must not be set until after the corresponding byp_warm_rst bit has been cleared or the PLL will immediately enter bypass mode.Field values (others are reserved):1'b0 - Disable Software control of exit from bypass mode1'b1 - Enable Software control of exit from bypass mode Reset Source: sys_por_rst_n
  [23] MCU_PLL_CLKSEL_BYP_WARM_RST — PLL bypass mode after warm reset.This bit is only valid when bypass_sw_ovrd is set to 1'b1 to enable bypass software override.This bit is set (1'b1) when a MCU warm reset occurs and will keep MCU_PLL0 in bypass mode after reset exit until cleared by software.Field values (others are reserved):1'b0 - EXIT_BYPASS1'b1 - MAINTAIN_BYPASS Reset Source: mcu_chip1_rst_n
  [8] MCU_PLL_CLKSEL_CLKLOSS_SWTCH_EN — When set, enables automatic switching of MCU_PLL0 clock source to CLK_12M_RC if HFOSC0 clock loss is detectedField values (others are reserved):1'b0 - Disable clock source switching on clock loss1'b1 - Enable clock source switching on clock loss Reset Source: mod_por_rst_n
0x8058 MCU_CTRL_MMRCFG0_DEVICE_CLKOUT_32K_CTRL — Selects which 32KHz Clock Source provides the 32KHz clock to the Device.
  [1:0] DEVICE_CLKOUT_32K_CTRL_CLK_32K_RC_SEL — Selects the source of the device level 32KHz ClockField values (others are reserved):2'b00 - CLK_32K_RC2'b01 - HFOSC0_CLKOUT_32Kundefined - undefined2'b11 - LFOSC0_CLKOUT Reset Source: mod_g_rst_n
0x8070 MCU_CTRL_MMRCFG0_MCU_GPIO_CLKSEL access not given reset not defined — Controls the functional clock source for MCU_GPIO
0x9100 MCU_CTRL_MMRCFG0_CLAIMREG_P2_R0_READONLY ro
  [31:0] CLAIMREG_P2_R0_READONLY — Claim bits for Partition 2 Reset Source: mod_g_rst_n
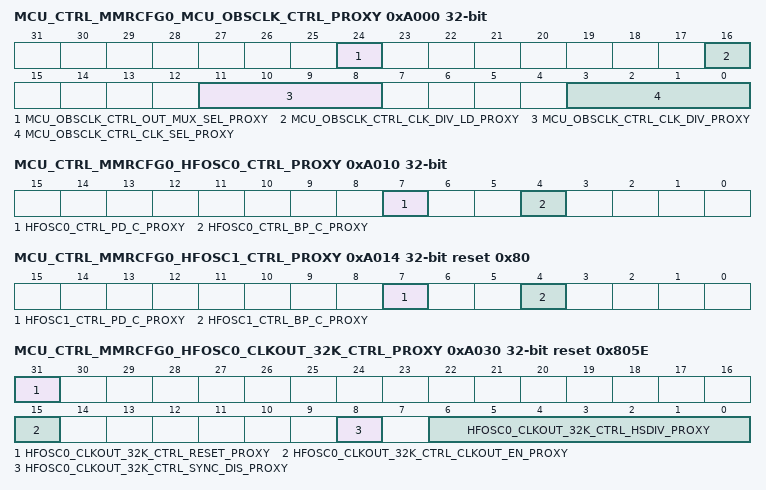
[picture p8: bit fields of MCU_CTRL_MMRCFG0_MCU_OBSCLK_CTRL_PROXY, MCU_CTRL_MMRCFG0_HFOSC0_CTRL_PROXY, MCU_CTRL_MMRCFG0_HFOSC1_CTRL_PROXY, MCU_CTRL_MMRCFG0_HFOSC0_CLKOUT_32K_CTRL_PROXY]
0xA000 MCU_CTRL_MMRCFG0_MCU_OBSCLK_CTRL_PROXY — Controls which internal clock is made observable on the MCU_OBSCLK output pin
  [24] MCU_OBSCLK_CTRL_OUT_MUX_SEL_PROXY — MCU_OBSCLK pin output mux selection.Note, HFOSC0_CLK is a direct output from the HFOSC0, distinct from HFOSC0_CLKOUT.Note, when HFOSC0_CLK is selected (1'b1) the MCU_OBSCLK_CTRL_clk_sel field must be programmed to 4'b0001.Field values (others are reserved):1'b0 - CLK_DIV_OUT1'b1 - HFOSC0_CLK (clk_sel must be OFF) Reset Source: mod_por_rst_n
  [16] MCU_OBSCLK_CTRL_CLK_DIV_LD_PROXY — Load the output divider valueWriting 1 to this bit will generate a load pulse to load the OBSCLK divider value. This bit can be cleared but must not be set in the same write cycle in which the clk_div value is changed. Field values (others are reserved):1'b0 - READY1'b1 - LOAD Reset Source: mod_por_rst_n
  [11:8] MCU_OBSCLK_CTRL_CLK_DIV_PROXY — MCU_OBSCLK pin clock selection output dividerOutput clock is divided by clk_div+1 Reset Source: mod_por_rst_n
  [3:0] MCU_OBSCLK_CTRL_CLK_SEL_PROXY — MCU_OBSCLK pin clock selectionField values (others are reserved):4'b0000 - CLK_12M_RC4'b0001 - OFF4'b0010 - MCU_PLL0_HSDIV0_CLKOUT4'b0011 - MCU_PLL0_HSDIV4_CLKOUT4'b0100 - MCU_PLLCTRL_OBSCLK4'b0101 - CLK_32K_RC4'b0110 - HFOSC0_CLKOUT4'b0111 - HFOSC0_CLKOUT_32K4'b1000 - MCU_SYSCLK04'b1001 - DEVICE_CLKOUT_32K Reset Source: mod_por_rst_n
0xA010 MCU_CTRL_MMRCFG0_HFOSC0_CTRL_PROXY — Controls the operation of oscillator 0
  [7] HFOSC0_CTRL_PD_C_PROXY — Oscillator powerdown control. When set, oscillator is disabled. Oscillator output is tristated if bp_c=0Field values (others are reserved):1'b0 - ACTIVE1'b1 - POWERDOWN Reset Source: mod_por_rst_n
  [4] HFOSC0_CTRL_BP_C_PROXY — Must write '0' Reset Source: mod_por_rst_n
0xA014 MCU_CTRL_MMRCFG0_HFOSC1_CTRL_PROXY reset 0x80 — Controls the operation of oscillator 1
  [7] HFOSC1_CTRL_PD_C_PROXY — Oscillator powerdown control. When set, oscillator is disabled. Oscillator output is tristated if bp_c=0Field values (others are reserved):1'b0 - ACTIVE1'b1 - POWERDOWN Reset Source: mod_por_rst_n
  [4] HFOSC1_CTRL_BP_C_PROXY — Must write '0' Reset Source: mod_por_rst_n
0xA020 MCU_CTRL_MMRCFG0_HFOSC0_STAT_PROXY access not given reset not defined — Allows status of the HFOSC Power Down by DM to be read by Top Level.
0xA030 MCU_CTRL_MMRCFG0_HFOSC0_CLKOUT_32K_CTRL_PROXY reset 0x805E — Controls the HSDIV that generates a 32KHz RT clock from the HFOSC0 Crystal
  [31] HFOSC0_CLKOUT_32K_CTRL_RESET_PROXY — Asynchronous Divider Reset.Field values (others are reserved):1'b0 - ACTIVE1'b1 - RESET Reset Source: sys_por_rst_n
  [15] HFOSC0_CLKOUT_32K_CTRL_CLKOUT_EN_PROXY — HFOSC0_CLKOUT_32K output activeField values (others are reserved):1'b0 - Disabled1'b1 - Enabled Reset Source: sys_por_rst_n
  [8] HFOSC0_CLKOUT_32K_CTRL_SYNC_DIS_PROXY — HFOSC0_CLKOUT_32K Synchronize DisableThis bit must be written 0.Field values (others are reserved):1'b0 - NORMAL Reset Source: sys_por_rst_n
  [6:0] HFOSC0_CLKOUT_32K_CTRL_HSDIV_PROXY — HFOSC0_CLKOUT_32K divider:HFOSC0_CLKKOUT_32K Frequency = HFOSC0 Frequency / [8 * (hsdiv + 1)]Ex. HFOSC0 Frequency = 25MHz. hsdiv = 94 (Default)HFOSC0_CLKOUT_32K = 25MHz / (8 * (94+1)) = 26MHz / 760 = 32.894 kHz Reset Source: sys_por_rst_n
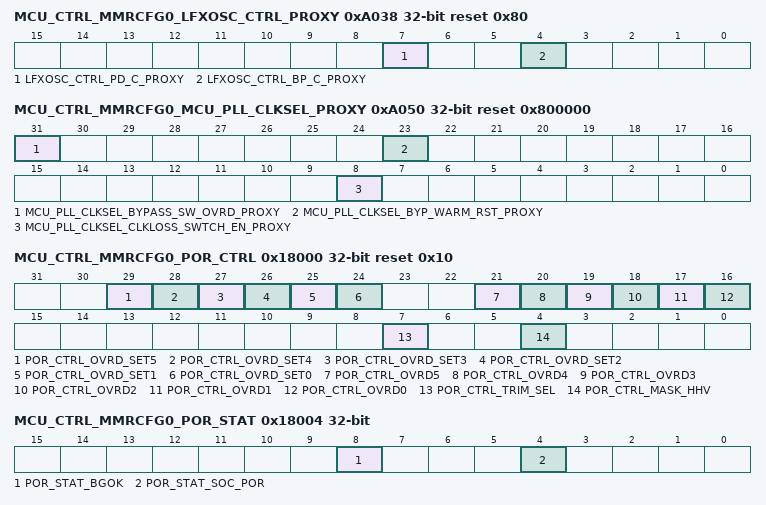
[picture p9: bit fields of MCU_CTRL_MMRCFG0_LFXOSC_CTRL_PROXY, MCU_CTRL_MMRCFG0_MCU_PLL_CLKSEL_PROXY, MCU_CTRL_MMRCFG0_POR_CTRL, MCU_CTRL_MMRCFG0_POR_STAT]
0xA038 MCU_CTRL_MMRCFG0_LFXOSC_CTRL_PROXY reset 0x80 — Controls the operation of the low frequency oscillator
  [7] LFXOSC_CTRL_PD_C_PROXY — Oscillator powerdown control. When set, oscillator is disabled. Oscillator output is tristated if bp_c=0Field values (others are reserved):1'b0 - ACTIVE1'b1 - POWERDOWN Reset Source: mod_por_rst_n
  [4] LFXOSC_CTRL_BP_C_PROXY — Oscillator bypass control. When set, oscillator is in bypass modeField values (others are reserved):1'b0 - ACTIVE1'b1 - BYPASS Reset Source: mod_por_rst_n
0xA050 MCU_CTRL_MMRCFG0_MCU_PLL_CLKSEL_PROXY reset 0x800000 — Controls the clock source for MCU PLL
  [31] MCU_PLL_CLKSEL_BYPASS_SW_OVRD_PROXY — PLL Bypass warm reset software overrideWhen set, enables software control of exit from bypass mode on a mcu_reset_z for MCU_PLL0. This bit must not be set until after the corresponding byp_warm_rst bit has been cleared or the PLL will immediately enter bypass mode.Field values (others are reserved):1'b0 - Disable Software control of exit from bypass mode1'b1 - Enable Software control of exit from bypass mode Reset Source: sys_por_rst_n
  [23] MCU_PLL_CLKSEL_BYP_WARM_RST_PROXY — PLL bypass mode after warm reset.This bit is only valid when bypass_sw_ovrd is set to 1'b1 to enable bypass software override.This bit is set (1'b1) when a MCU warm reset occurs and will keep MCU_PLL0 in bypass mode after reset exit until cleared by software.Field values (others are reserved):1'b0 - EXIT_BYPASS1'b1 - MAINTAIN_BYPASS Reset Source: mcu_chip1_rst_n
  [8] MCU_PLL_CLKSEL_CLKLOSS_SWTCH_EN_PROXY — When set, enables automatic switching of MCU_PLL0 clock source to CLK_12M_RC if HFOSC0 clock loss is detectedField values (others are reserved):1'b0 - Disable clock source switching on clock loss1'b1 - Enable clock source switching on clock loss Reset Source: mod_por_rst_n
0xA058 MCU_CTRL_MMRCFG0_DEVICE_CLKOUT_32K_CTRL_PROXY — Selects which 32KHz Clock Source provides the 32KHz clock to the Device.
  [1:0] DEVICE_CLKOUT_32K_CTRL_CLK_32K_RC_SEL_PROXY — Selects the source of the device level 32KHz ClockField values (others are reserved):2'b00 - CLK_32K_RC2'b01 - HFOSC0_CLKOUT_32Kundefined - undefined2'b11 - LFOSC0_CLKOUT Reset Source: mod_g_rst_n
0xA070 MCU_CTRL_MMRCFG0_MCU_GPIO_CLKSEL_PROXY access not given reset not defined — Controls the functional clock source for MCU_GPIO
0xB100 MCU_CTRL_MMRCFG0_CLAIMREG_P2_R0
  [31:0] CLAIMREG_P2_R0 — Claim bits for Partition 2 Reset Source: mod_g_rst_n
0x11008 MCU_CTRL_MMRCFG0_LOCK4_KICK0
  [31:0] LOCK4_KICK0 — - KICK0 component Reset Source: mod_g_rst_n
0x1100C MCU_CTRL_MMRCFG0_LOCK4_KICK1
  [31:0] LOCK4_KICK1 — - KICK1 component Reset Source: mod_g_rst_n
0x13008 MCU_CTRL_MMRCFG0_LOCK4_KICK0_PROXY
  [31:0] LOCK4_KICK0_PROXY — - KICK0 component Reset Source: mod_g_rst_n
0x1300C MCU_CTRL_MMRCFG0_LOCK4_KICK1_PROXY
  [31:0] LOCK4_KICK1_PROXY — - KICK1 component Reset Source: mod_g_rst_n
{0x13100+4i} MCU_CTRL_MMRCFG0_CLAIMREG_P4_R{i} (i=0..19)
  [31:0] CLAIMREG_P4_R{i} — Claim bits for Partition 4 Reset Source: mod_g_rst_n
0x18000 MCU_CTRL_MMRCFG0_POR_CTRL reset 0x10 — Configures POR module reset behavior and allows software to directly override POR comparator outputs.
  [29] POR_CTRL_OVRD_SET5 — Override value when override is active, for RESERVED output.Field values (others are reserved):1'b0 - OVERRIDE_TO_01'b1 - OVERRIDE_TO_1 Reset Source: mod_por_rst_n
  [28] POR_CTRL_OVRD_SET4 — Override value when override is active, for POKLVB output.Field values (others are reserved):1'b0 - OVERRIDE_TO_01'b1 - OVERRIDE_TO_1 Reset Source: mod_por_rst_n
  [27] POR_CTRL_OVRD_SET3 — Override value when override is active, for POKLVA output.Field values (others are reserved):1'b0 - OVERRIDE_TO_01'b1 - OVERRIDE_TO_1 Reset Source: mod_por_rst_n
  [26] POR_CTRL_OVRD_SET2 — Override value when override is active, for POKHV output.Field values (others are reserved):1'b0 - OVERRIDE_TO_01'b1 - OVERRIDE_TO_1 Reset Source: mod_por_rst_n
  [25] POR_CTRL_OVRD_SET1 — Override value when override is active, for BGOK output.Field values (others are reserved):1'b0 - OVERRIDE_TO_01'b1 - OVERRIDE_TO_1 Reset Source: mod_por_rst_n
  [24] POR_CTRL_OVRD_SET0 — Override value when override is active, for PORHV output.Field values (others are reserved):1'b0 - OVERRIDE_TO_01'b1 - OVERRIDE_TO_1 Reset Source: mod_por_rst_n
  [21] POR_CTRL_OVRD5 — Enables override of RESERVED outputField values (others are reserved):1'b0 - NORMAL_OPERATION1'b1 - OVERRIDE_OUTPUT Reset Source: mod_por_rst_n
  [20] POR_CTRL_OVRD4 — Enables override of POKLVB outputField values (others are reserved):1'b0 - NORMAL_OPERATION1'b1 - OVERRIDE_OUTPUT Reset Source: mod_por_rst_n
  [19] POR_CTRL_OVRD3 — Enables override of POKLVA outputField values (others are reserved):1'b0 - NORMAL_OPERATION1'b1 - OVERRIDE_OUTPUT Reset Source: mod_por_rst_n
  [18] POR_CTRL_OVRD2 — Enables override of POKHV outputField values (others are reserved):1'b0 - NORMAL_OPERATION1'b1 - OVERRIDE_OUTPUT Reset Source: mod_por_rst_n
  [17] POR_CTRL_OVRD1 — Enables override of BGOK outputField values (others are reserved):1'b0 - NORMAL_OPERATION1'b1 - OVERRIDE_OUTPUT Reset Source: mod_por_rst_n
  [16] POR_CTRL_OVRD0 — Enables override of PORHV outputField values (others are reserved):1'b0 - NORMAL_OPERATION1'b1 - OVERRIDE_OUTPUT Reset Source: mod_por_rst_n
  [7] POR_CTRL_TRIM_SEL — POR Trim Select - Fixed value or from POR_BANDGAP_CTRL and POR_POKxxx_CTRL registers MMRsField values (others are reserved):1'b0 - FIXED_TRIM1'b1 - MMR_TRIM Reset Source: mod_por_rst_n
  [4] POR_CTRL_MASK_HHV — Mask HHV/SOC_PORz outputs when applying new trim valuesField values (others are reserved):1'b0 - UNMASK1'b1 - MASK Reset Source: mod_por_rst_n
0x18004 MCU_CTRL_MMRCFG0_POR_STAT ro — Shows POR module status
  [8] POR_STAT_BGOK — Bandgap OK statusField values (others are reserved):1'b0 - UNKNOWN1'b1 - OK Reset Source: mod_por_rst_n
  [4] POR_STAT_SOC_POR — POR module statusField values (others are reserved):1'b0 - POR_IS_ACTIVE1'b1 - POR_IS_RESET Reset Source: mod_por_rst_n
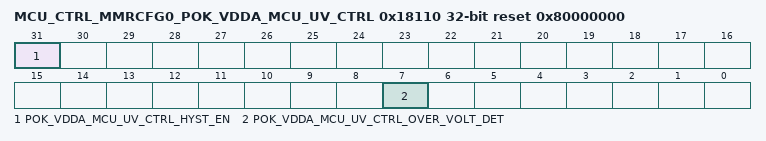
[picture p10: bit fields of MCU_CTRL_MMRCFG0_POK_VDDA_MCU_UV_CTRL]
0x18110 MCU_CTRL_MMRCFG0_POK_VDDA_MCU_UV_CTRL reset 0x80000000 — Hysterisis, Threshold, and Control of VDDA_MCU 1P8 Under/Over Voltage Monitors in POR (POKHV, POKLVA)
  [31] POK_VDDA_MCU_UV_CTRL_HYST_EN — Enable POK hysteresisField values (others are reserved):1'b0 - DISABLE1'b1 - ENABLE Reset Source: mod_por_rst_n
  [7] POK_VDDA_MCU_UV_CTRL_OVER_VOLT_DET — Over / under voltage detection modeField values (others are reserved):1'b0 - UNDERVOLTAGE_MODE1'b1 - OVERVOLTAGE_MODE Reset Source: mod_por_rst_n
